# CM_DPLL register map
Vendor: Texas Instruments
Peripheral module from a debugger description file (folder am437x).
Registers are 32-bit, access per field, no defined reset value unless marked. A register's access mark holds for its fields unless they carry their own. Offsets are as the file gives them; lines under a group give offsets from that group; [hi:lo] are bit positions; {n}, {i} and the like mark numbered series; 'fields as' and 'values as' point back to an identical list; <NAME> marks a mode.

## CM_DPLL
0x00 PRCM_CM_DPLL_DPLL_CLKSEL_TIMER1_CLK — Selects the Mux select line for TIMER1 clock [warm reset insensitive]
  [2:0] CLKSEL rw — Selects the Mux select line for DMTIMER_1MS clock [warm reset insensitive]
    5=en_6_0x5 (Reserved); 4=en_5_0x4 (Selects the 32KHz clock from RTC 32KHz Crystal Osc); 3=en_4_0x3 (Select CLK_RC32K clock); 2=en_3_0x2 (Select TCLKIN clock); 1=en_2_0x1 (Select CLK_32KHZ clock from PER_PLL divided clock); 0=en_1_0x0 (Select CLK_M_OSC clock)
0x04 PRCM_CM_DPLL_CLKSEL_TIMER2_CLK — Selects the Mux select line for TIMER2 clock [warm reset insensitive]
  [1:0] CLKSEL rw
    3=en_4_0x3 (Reserved); 2=en_3_0x2 (Select CLK_32KHZ clock); 1=en_2_0x1 (Select CLK_M_OSC clock); 0=en_1_0x0 (Select TCLKIN clock)
0x08 PRCM_CM_DPLL_CLKSEL_TIMER3_CLK — Selects the Mux select line for TIMER3 clock [warm reset insensitive]
  fields as PRCM_CM_DPLL_CLKSEL_TIMER2_CLK
0x0C PRCM_CM_DPLL_CLKSEL_TIMER4_CLK — Selects the Mux select line for TIMER4 clock [warm reset insensitive]
  fields as PRCM_CM_DPLL_CLKSEL_TIMER2_CLK
0x10 PRCM_CM_DPLL_CLKSEL_TIMER5_CLK — Selects the Mux select line for TIMER5 clock [warm reset insensitive]
  fields as PRCM_CM_DPLL_CLKSEL_TIMER2_CLK
0x14 PRCM_CM_DPLL_CLKSEL_TIMER6_CLK — Selects the Mux select line for TIMER6 clock [warm reset insensitive]
  fields as PRCM_CM_DPLL_CLKSEL_TIMER2_CLK
0x18 PRCM_CM_DPLL_CLKSEL_TIMER7_CLK — Selects the Mux select line for TIMER7 clock [warm reset insensitive]
  fields as PRCM_CM_DPLL_CLKSEL_TIMER2_CLK
0x1C PRCM_CM_DPLL_CLKSEL_TIMER8_CLK — Selects the Mux select line for TIMER8 clock [warm reset insensitive]
  fields as PRCM_CM_DPLL_CLKSEL_TIMER2_CLK
0x20 PRCM_CM_DPLL_CLKSEL_TIMER9_CLK — Selects the Mux select line for TIMER9 clock [warm reset insensitive]
  fields as PRCM_CM_DPLL_CLKSEL_TIMER2_CLK
0x24 PRCM_CM_DPLL_CLKSEL_TIMER10_CLK — Selects the Mux select line for TIMER10 clock [warm reset insensitive]
  fields as PRCM_CM_DPLL_CLKSEL_TIMER2_CLK
0x28 PRCM_CM_DPLL_CLKSEL_TIMER11_CLK — Selects the Mux select line for TIMER11 clock [warm reset insensitive]
  fields as PRCM_CM_DPLL_CLKSEL_TIMER2_CLK
0x2C PRCM_CM_DPLL_CLKSEL_WDT1_CLK — Selects the Mux select line for Watchdog1 clock [warm reset insensitive]
  [0] CLKSEL rw — Selects the Mux select line for WDT1 clock [warm reset insensitive]
    1=en_2_0x1 (Select 32KHZ from 32K Clock divider); 0=en_1_0x0 (Select 32KHZ clock from RC Oscillator)
0x30 PRCM_CM_DPLL_CLKSEL_SYNCTIMER_CLK — Selects the Mux select line for SYNCTIMER clock [warm reset insensitive]
  [1:0] CLKSEL rw — Selects the Mux select line for SYNCTIMER clock
    3=en_4_0x3 (Reserved); 2=en_3_0x2 (Select PER PLL 32KHz clock); 1=en_2_0x1 (Reserved); 0=en_1_0x0 (Select RTC 32K clock)
0x34 PRCM_CM_DPLL_CLKSEL_MAC_CLK — Selects the clock divide ration for MII clock [warm reset insensitive]
  [2] MII_CLK_SEL rw — MII Clock Divider Selection. [[br]]This bit is warm reset insensitive when CPSW RESET_ISO is enabled
    1=en_2_0x1 (Selects 1/5 divide ratio of SYSCLK2); 0=en_1_0x0 (Selects 1/2 divider of SYSCLK2)
0x38 PRCM_CM_DPLL_CLKSEL_CPTS_RFT_CLK — Selects the Mux select line for CPTS RFT clock [warm reset insensitive]
  [1:0] CLKSEL rw — Selects the Mux select line for cpgmac rft clock [warm reset insensitive]
    2=en_3_0x2 (Selects DISP PLL clock as CPTS RFT Clock); 1=en_2_0x1 (Select HSDIVIDE_CORE M5 Output); 0=en_1_0x0 (Select HSDIVIDER_CORE M4 output)
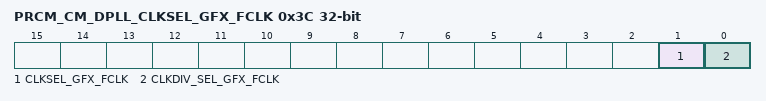
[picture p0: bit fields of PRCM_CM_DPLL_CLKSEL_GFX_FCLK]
0x3C PRCM_CM_DPLL_CLKSEL_GFX_FCLK — Selects the divider value for GFX clock [warm reset insensitive]
  [1] CLKSEL_GFX_FCLK rw — Selects the clock on gfx fclk [warm reset insensitive]
    1=en_2_0x1 (SGX FCLK is from PER PLL (192 MHz clock)); 0=en_1_0x0 (SGX FCLK is from CORE PLL (same as L3 clock))
  [0] CLKDIV_SEL_GFX_FCLK rw — Selects the divider value on gfx fclk [warm reset insensitive]
    1=en_2_0x1 (SGX FCLK is L3 clock/2 or 192Mhz/2); 0=en_1_0x0 (SGX FCLK is same as L3 Clock or 192MHz Clock)
0x40 PRCM_CM_DPLL_CLKSEL_GPIO0_DBCLK — Selects the Mux select line for GPIO0 debounce clock [warm reset insensitive]
  [2:0] CLKSEL rw
    4=en_5_0x4 (Reserved); 3=en_4_0x3 (Select 32KHz from SYS_CLK (Source: main XTAL oscillator clock) Clock Divider); 2=en_3_0x2 (Select 32KHz from PER_PLL (Source: 192MHz) Clock Divider); 1=en_2_0x1 (Select 32KHZ from 32K Crystal Oscillator); 0=en_1_0x0 (Select 32KHZ clock from RC Oscillator)
0x48 PRCM_CM_CLKSEL_PRU_ICSS_OCP_CLK — Controls Mux Select of PRU-ICSS OCP clock mux
  [0] CLKSEL rw
    1=en_2_0x1 (Select DISP DPLL clock as OCP clock of PRU-ICSS); 0=en_1_0x0 (Select L3F clock as OCP Clock of PRU-ICSS)
0x4C PRCM_CM_CLKSEL_ADC1_CLK — Selects the Mux select line for ADC1 clock [warm reset insensitive]
  [0] CLKSEL rw
    1=en_2_0x1 (Select 192MHz PER PLL clock output as ADC1 clock); 0=en_1_0x0 (Select Main Crystal clock as ADC1 clock)
0x50 PRCM_CM_DPLL_CLKSEL_DLL_AGING_CLK — Selects the clock divider for DLL_AGING module clock [warm reset insensitive]
  [1:0] CLKSEL rw — Selects the divider value for generating the DLL_AGING clock
    3=en_4_0x3 (Reserved); 2=en_3_0x2 (Divide by 32); 1=en_2_0x1 (Divide by 16); 0=en_1_0x0 (Divide by 8)
0x60 PRCM_CM_DPLL_CLKSEL_USBPHY32KHZ_GCLK — Selects the Mux select line for USBPHY 32KHZ clock [warm reset insensitive]
  [0] CLKSEL rw — Selects the Mux select line for USBPHY 32KHZ clock
    0=en_1_0x0 (Select RTC 32K clock)
